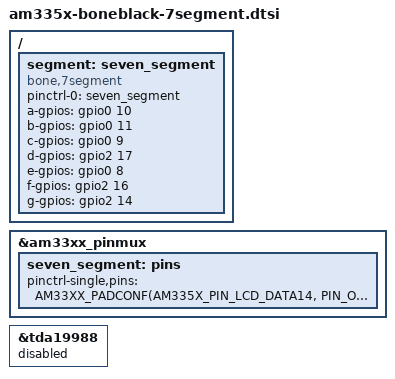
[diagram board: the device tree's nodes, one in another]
/ {
	segment: seven_segment {
		compatible = "bone,7segment";
		pinctrl-names = "default";
		pinctrl-0 = <&seven_segment>;

		a-gpios = <&gpio0 10 GPIO_ACTIVE_HIGH>;
		b-gpios = <&gpio0 11 GPIO_ACTIVE_HIGH>;
		c-gpios = <&gpio0 9 GPIO_ACTIVE_HIGH>;
		d-gpios = <&gpio2 17 GPIO_ACTIVE_HIGH>;
		e-gpios = <&gpio0 8 GPIO_ACTIVE_HIGH>;
		f-gpios = <&gpio2 16 GPIO_ACTIVE_HIGH>;
		g-gpios = <&gpio2 14 GPIO_ACTIVE_HIGH>;
	};
};

&am33xx_pinmux {
	seven_segment: pins {
		pinctrl-single,pins = <
			AM33XX_PADCONF(AM335X_PIN_LCD_DATA14, PIN_OUTPUT, MUX_MODE7)
			AM33XX_PADCONF(AM335X_PIN_LCD_DATA15, PIN_OUTPUT, MUX_MODE7)
			AM33XX_PADCONF(AM335X_PIN_LCD_DATA13, PIN_OUTPUT, MUX_MODE7)
			AM33XX_PADCONF(AM335X_PIN_LCD_DATA11, PIN_OUTPUT, MUX_MODE7)
			AM33XX_PADCONF(AM335X_PIN_LCD_DATA12, PIN_OUTPUT, MUX_MODE7)
			AM33XX_PADCONF(AM335X_PIN_LCD_DATA10, PIN_OUTPUT, MUX_MODE7)
			AM33XX_PADCONF(AM335X_PIN_LCD_DATA8, PIN_OUTPUT, MUX_MODE7)
		>;
	};
};

&tda19988 {
	status = "disabled";
};
